# ATxmega384D3 device description
Architecture: AVR8_XMEGA; Family: AVR XMEGA
Registers are 8-bit, access not given, no defined reset value unless marked. A register's access mark holds for its fields unless they carry their own. Offsets are from the block's base; [hi:lo] are bit positions; {n}, {i} and the like mark numbered series; 'fields as' and 'values as' point back to an identical list.

## DFLL
Instances: DFLLRC32M 0x0060, DFLLRC2M 0x0068
0x00 CTRL — Control Register
  [0] ENABLE — DFLL Enable
0x02 CALA — Calibration Register A
  [6:0] CALL — DFLL Calibration Value A
0x03 CALB — Calibration Register B
  [5:0] CALH — DFLL Calibration Value B
{0x4+i} COMP{i} (i=0..2) — Oscillator Compare Register {i}

## RST — Reset
Instances: RST 0x0078
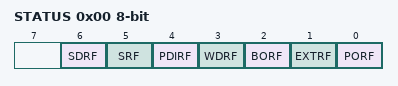
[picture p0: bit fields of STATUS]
0x00 STATUS
  [6] SDRF — Spike Detection Reset Flag
  [5] SRF — Software Reset Flag
  [4] PDIRF — Programming and Debug Interface Interface Reset Flag
  [3] WDRF — Watchdog Reset Flag
  [2] BORF — Brown-out Reset Flag
  [1] EXTRF — External Reset Flag
  [0] PORF — Power-on Reset Flag
0x01 CTRL — Control Register
  [0] SWRST — Software Reset

## WDT — Watch-Dog Timer
Instances: WDT 0x0080
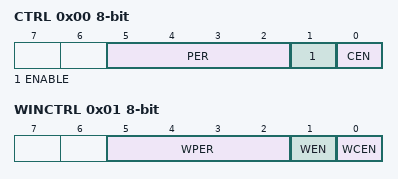
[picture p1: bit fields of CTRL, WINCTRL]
0x00 CTRL — Control
  [5:2] PER — Period
    0=8CLK (8 cycles (8ms @ 3.3V)); 1=16CLK (16 cycles (16ms @ 3.3V)); 2=32CLK (32 cycles (32ms @ 3.3V)); 3=64CLK (64 cycles (64ms @ 3.3V)); 4=128CLK (128 cycles (0.128s @ 3.3V)); 5=256CLK (256 cycles (0.256s @ 3.3V)); 6=512CLK (512 cycles (0.512s @ 3.3V)); 7=1KCLK (1K cycles (1s @ 3.3V)); 8=2KCLK (2K cycles (2s @ 3.3V)); 9=4KCLK (4K cycles (4s @ 3.3V)); 10=8KCLK (8K cycles (8s @ 3.3V))
  [1] ENABLE
  [0] CEN — Change Enable
0x01 WINCTRL — Windowed Mode Control
  [5:2] WPER — Windowed Mode Period
    values as CTRL.PER
  [1] WEN — Windowed Mode Enable
  [0] WCEN — Windowed Mode Change Enable
0x02 STATUS
  [0] SYNCBUSY — Syncronization busy

## MCU — MCU Control
Instances: MCU 0x0090
{0x0+i} DEVID{i} (i=0..2) — Device ID byte {i}
0x03 REVID — Revision ID
0x07 ANAINIT — Analog Startup Delay
  [1:0] STARTUPDLYA — Analog startup delay Port A
0x08 EVSYSLOCK — Event System Lock
  [0] EVSYS0LOCK — Event Channel 0-3 Lock
0x09 AWEXLOCK
  [0] AWEXCLOCK — AWeX on T/C C0 Lock

## PMIC — Programmable Multi-level Interrupt Controller
Instances: PMIC 0x00A0
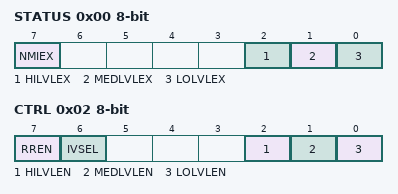
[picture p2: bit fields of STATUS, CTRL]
0x00 STATUS
  [7] NMIEX — Non-maskable Interrupt Executing
  [2] HILVLEX — High Level Interrupt Executing
  [1] MEDLVLEX — Medium Level Interrupt Executing
  [0] LOLVLEX — Low Level Interrupt Executing
0x01 INTPRI — Interrupt Priority
0x02 CTRL — Control Register
  [7] RREN — Round-Robin Priority Enable
  [6] IVSEL — Interrupt Vector Select
  [2] HILVLEN — High Level Enable
  [1] MEDLVLEN — Medium Level Enable
  [0] LOLVLEN — Low Level Enable

## PORTCFG — I/O port Configuration
Instances: PORTCFG 0x00B0
0x00 MPCMASK — Multi-pin Configuration Mask
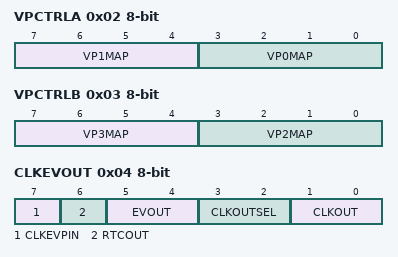
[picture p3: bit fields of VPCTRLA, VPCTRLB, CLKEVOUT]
0x02 VPCTRLA — Virtual Port Control Register A
  [7:4] VP1MAP — Virtual Port 1 Mapping
    0=PORTA (Mapped To PORTA); 1=PORTB (Mapped To PORTB); 2=PORTC (Mapped To PORTC); 3=PORTD (Mapped To PORTD); 4=PORTE (Mapped To PORTE); 5=PORTF (Mapped To PORTF); 6=PORTG (Mapped To PORTG); 7=PORTH (Mapped To PORTH); 8=PORTJ (Mapped To PORTJ); 9=PORTK (Mapped To PORTK); 10=PORTL (Mapped To PORTL); 11=PORTM (Mapped To PORTM); 12=PORTN (Mapped To PORTN); 13=PORTP (Mapped To PORTP); 14=PORTQ (Mapped To PORTQ); 15=PORTR (Mapped To PORTR)
  [3:0] VP0MAP — Virtual Port 0 Mapping
    values as VP1MAP
0x03 VPCTRLB — Virtual Port Control Register B
  [7:4] VP3MAP — Virtual Port 3 Mapping
    values as VPCTRLA.VP1MAP
  [3:0] VP2MAP — Virtual Port 2 Mapping
    values as VPCTRLA.VP1MAP
0x04 CLKEVOUT — Clock and Event Out Register
  [7] CLKEVPIN — Peripheral Clock and Event Output pin Select
    0=PIN7 (Clock and Event Output on PIN 7); 1=PIN4 (Clock and Event Output on PIN 4)
  [6] RTCOUT — RTC Clock Output
  [5:4] EVOUT — Event Output Port
    0=OFF (Event Output Disabled); 1=PC7 (Event Channel 7 Output on Port C pin 7); 2=PD7 (Event Channel 7 Output on Port D pin 7); 3=PE7 (Event Channel 7 Output on Port E pin 7)
  [3:2] CLKOUTSEL — Peripheral Clock Output Select
    0=CLK1X (1x Peripheral Clock Output to pin); 1=CLK2X (2x Peripheral Clock Output to pin); 2=CLK4X (4x Peripheral Clock Output to pin)
  [1:0] CLKOUT — Peripheral Clock Output Port
    0=OFF (System Clock Output Disabled); 1=PC7 (System Clock Output on Port C pin 7); 2=PD7 (System Clock Output on Port D pin 7); 3=PE7 (System Clock Output on Port E pin 7)
0x06 EVOUTSEL — Event Output Select
  [2:0] EVOUTSEL
    {v}=Event Channel {v} output to pin (v=0..7)
